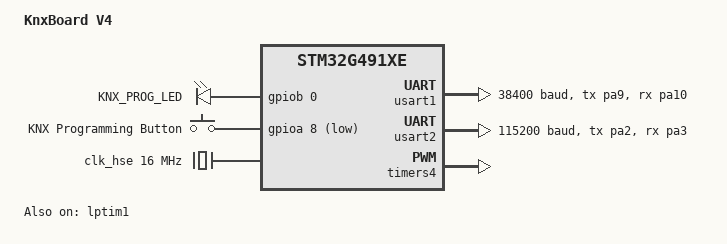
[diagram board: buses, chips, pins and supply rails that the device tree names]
/*
 * KnxBoard V4 — KNX TP1 board, STM32G491KEU + onsemi NCN5130.
 * Project: https://github.com/condo4/knxboard/tree/master
 *
 * Copyright (c) 2024 Klaus Nagel, <nagelkl01@gmail.com>
 *
 * SPDX-License-Identifier: Apache-2.0
 */

/dts-v1/;
#include <st/g4/stm32g491Xe.dtsi>
#include <st/g4/stm32g491k(c-e)ux-pinctrl.dtsi>
#include <zephyr/dt-bindings/input/input-event-codes.h>

/ {
	model = "KnxBoard V4";
	compatible = "kazoe,knxboardv4";

	chosen {
		zephyr,console = &usart2;
		zephyr,shell-uart = &usart2;
		zephyr,sram = &sram0;
		zephyr,flash = &flash0;
		zephyr,system-timer = &lptim1;
		knx_prog_led = &knx_prog_led;
	};

	ncn5130: ncn5130 {
		compatible = "onnn,ncn5130";
		uart = <&usart1>;
		status = "okay";
	};

	leds: leds {
		compatible = "gpio-leds";

		knx_prog_led: led_0 {
			gpios = <&gpiob 0 GPIO_ACTIVE_HIGH>;
			label = "KNX_PROG_LED";
		};
	};

	buttons {
		compatible = "gpio-keys";
		debounce-interval-ms = <50>;
		knx_prog_btn: knx_prog_btn {
			gpios = <&gpioa 8 (GPIO_ACTIVE_LOW | GPIO_PULL_UP)>;
			zephyr,code = <INPUT_KEY_0>;
			label = "KNX Programming Button";
		};
	};

	aliases {
		led0 = &knx_prog_led;
		sw0  = &knx_prog_btn;
	};
};

&clk_lsi {
	status = "okay";
};

&clk_hse {
	hse-bypass;
	clock-frequency = <DT_FREQ_M(16)>; /* 16MHz from NCN5130 */
        status = "okay";
};

&lptim1 {
	clocks = <&rcc STM32_CLOCK(APB1, 31)>,
		 <&rcc STM32_SRC_LSI LPTIM1_SEL(1)>;
	status = "okay";
};

/* Adjust the pll for a SYSTEM Clock of 170MHz  */
&pll {
	div-m = <1>;
	mul-n = <16>;
	div-p = <2>;
	div-q = <2>;
	div-r = <2>;
	clocks = <&clk_hse>;
	status = "okay";
};

&rcc {
	clocks = <&pll>;
	clock-frequency = <DT_FREQ_M(128)>;
	ahb-prescaler = <1>;
	apb1-prescaler = <8>;
	apb2-prescaler = <8>;
};

&dma1 {
	status = "okay";
};

&dmamux1 {
	status = "okay";
};

/*
 * KNX interface: NCN5130 on USART1.  16-bit DMA items are mandatory because the
 * transceiver runs a 9-bit host link — see the long comment on &lpuart1 in
 * knxboardv5.dts for why the driver cannot infer this.
 */
&usart1 {
	dmas = <&dmamux1 2 0x19 (STM32_DMA_PERIPH_TX | STM32_DMA_MEM_16BITS |
				 STM32_DMA_PERIPH_16BITS)>,
	       <&dmamux1 1 0x18 (STM32_DMA_PERIPH_RX | STM32_DMA_MEM_16BITS |
				 STM32_DMA_PERIPH_16BITS)>;
	dma-names = "tx", "rx";
	pinctrl-0 = <&usart1_tx_pa9 &usart1_rx_pa10>;
	pinctrl-names = "default";
	current-speed = <38400>;
	status = "okay";
};

&usart2 {
	pinctrl-0 = <&usart2_tx_pa2 &usart2_rx_pa3>;
	pinctrl-names = "default";
	current-speed = <115200>;
	status = "okay";
};

&timers4 {
	st,prescaler = <10000>;
	status = "okay";

	pwm4: pwm {
		status = "okay";
		pinctrl-0 = <&tim4_ch3_pb8>;
		pinctrl-names = "default";
	};
};

/* PA8 used for KNX_PROG_BTN; PA9 used for USART1 TX */
&i2c2 {
	status = "disabled";
};

&flash0 {
	partitions {
		compatible = "fixed-partitions";
		#address-cells = <1>;
		#size-cells = <1>;

		/* 4 KB NVS storage at the last page of the 128 KB flash */
		storage_partition: partition@1f000 {
			label = "storage";
			reg = <0x0001f000 DT_SIZE_K(4)>;
		};
	};
};
